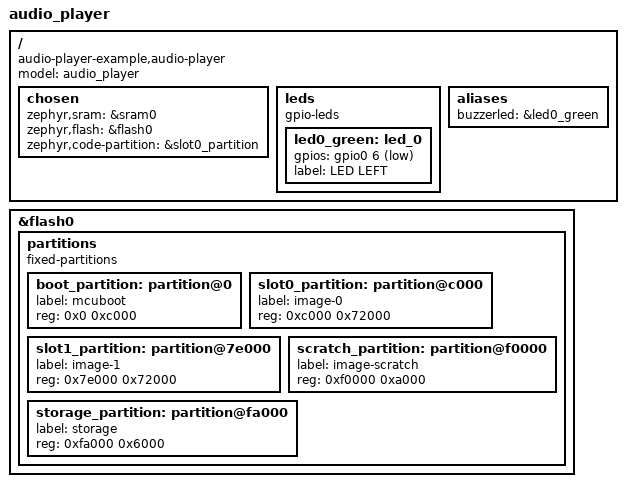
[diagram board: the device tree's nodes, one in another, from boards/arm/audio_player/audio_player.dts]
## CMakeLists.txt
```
# SPDX-License-Identifier: Apache-2.0

cmake_minimum_required(VERSION 3.20.0)

find_package(Zephyr REQUIRED HINTS $ENV{ZEPHYR_BASE})
project(nrf52-pwm-wav-sbc-decoder-player)

target_sources(app PRIVATE
  lib/sbc-1.5/sbc/sbc_primitives.c
  lib/sbc-1.5/sbc/sbc.c

  src/audio/PWMPlayer.cpp
  src/main.cpp
)

zephyr_include_directories(
  lib/sbc-1.5/sbc
  src/audio
  src
)
```

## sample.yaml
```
sample:
  description: NRF52 audio player with PWM output and sbc decoding
    application
  name: nrf52-pwm-with-opus-player
common:
    tags: introduction
    integration_platforms:
      - native_posix
    harness: console
```

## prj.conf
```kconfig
CONFIG_LOG=y
CONFIG_LOG_BUFFER_SIZE=2048
#CONFIG_BT_DEBUG_LOG=y

# kernel options
CONFIG_INIT_STACKS=y

CONFIG_NRFX_PWM=y
CONFIG_NRFX_PWM0=y

CONFIG_CONSOLE=y
CONFIG_USE_SEGGER_RTT=y
CONFIG_RTT_CONSOLE=y

CONFIG_NEWLIB_LIBC=y
CONFIG_MAIN_STACK_SIZE=4096
CONFIG_HEAP_MEM_POOL_SIZE=2048

# required for flashing with west and an external probe
# see https://developer.nordicsemi.com/nRF_Connect_SDK/doc/latest/zephyr/boards/arm/nrf52840dongle_nrf52840/doc/index.html#option-3-using-an-external-debug-probe
CONFIG_BOARD_HAS_NRF5_BOOTLOADER=n
```

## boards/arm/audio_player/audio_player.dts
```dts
// Copyright (c) 2021 Nordic Semiconductor ASA
// SPDX-License-Identifier: Apache-2.0

/dts-v1/;
#include <nordic/nrf52840_qiaa.dtsi>

/ {
	model = "audio_player";
	compatible = "audio-player-example,audio-player";

	chosen {
		zephyr,sram = &sram0;
		zephyr,flash = &flash0;
		zephyr,code-partition = &slot0_partition;
	};

	leds {
		compatible = "gpio-leds";
		led0_green: led_0 {
			gpios = <&gpio0 6 GPIO_ACTIVE_LOW>;
			label = "LED LEFT";
		};
	};

	aliases {
		buzzerled = &led0_green;
	};
};

&flash0 {
	partitions {
		compatible = "fixed-partitions";
		#address-cells = <1>;
		#size-cells = <1>;

		boot_partition: partition@0 {
			label = "mcuboot";
			reg = <0x0 0xc000>;
		};
		slot0_partition: partition@c000 {
			label = "image-0";
			reg = <0xc000 0x72000>;
		};
		slot1_partition: partition@7e000 {
			label = "image-1";
			reg = <0x7e000 0x72000>;
		};
		scratch_partition: partition@f0000 {
			label = "image-scratch";
			reg = <0xf0000 0xa000>;
		};
		storage_partition: partition@fa000 {
			label = "storage";
			reg = <0xfa000 0x6000>;
		};
	};
};
```

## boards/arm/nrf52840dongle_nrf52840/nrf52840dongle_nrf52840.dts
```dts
/dts-v1/;
#include <nordic/nrf52840_qiaa.dtsi>
```

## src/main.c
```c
#include <zephyr.h>
#include <device.h>
#include <devicetree.h>

#include <drivers/gpio.h>

#include <nrfx_pwm.h>
#include <hal/nrf_gpio.h>

#include "audio/buzzer02_16kHz.h"
#include "audio/buzzer01_16kHz.h"
#include "audio/decoder.h"

#include "nrf_pwm_audio.h"

#include <logging/log.h>
LOG_MODULE_REGISTER(main, CONFIG_LOG_DEFAULT_LEVEL);

#define LED0        DT_GPIO_LABEL(LED0_NODE, gpios)
#define LED0_NODE   DT_ALIAS(led0)
#define LED_PIN     DT_GPIO_PIN(LED0_NODE, gpios)
#define LED_FLAGS   DT_GPIO_FLAGS(LED0_NODE, gpios)

#define AUDIO_PIN NRF_GPIO_PIN_MAP(0,15)

void ledInit() {
	const struct device *dev = device_get_binding(LED0);	
	gpio_pin_configure(dev, LED_PIN, GPIO_OUTPUT_ACTIVE | LED_FLAGS);
}

void ledOn(bool on) {
	const struct device *dev = device_get_binding(LED0);
	gpio_pin_set(dev, LED_PIN, on);
}

void main(void) {

	LOG_INF("Playback time!");
	ledInit();
	
	IRQ_DIRECT_CONNECT(PWM0_IRQn, 0, nrfx_pwm_0_irq_handler, 0);
	nrf_pwm_audio_init(AUDIO_PIN, false);

	const size_t PCM_SIZE = 34688;
	unsigned char * pcmResult = (unsigned char *)k_malloc(PCM_SIZE);
    decodeSbcFile(&buzzer01_16kHz, buzzer01_16kHz_size, pcmResult);
	nrf_pwm_audio_playback(pcmResult, PCM_SIZE, NRF_PWM_AUDIO_SAMPLERATE_16K, 3.0, 0);

	ledOn(true);
	while (nrf_pwm_audio_is_playing()) { __WFE(); }
	ledOn(false);

	nrf_pwm_audio_stop();
	k_free(pcmResult);

  	while (1) {
		  k_msleep(2000);
	}
}
```

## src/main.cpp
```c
#include <zephyr.h>

#include <hal/nrf_gpio.h>

#include "audio/PWMPlayer.h"
#include "audio/AudioDecoderSbc.h"
#include "audio/AudioDecoderRaw.h"

#include "samples/sample_hit_raw.h"
#include "samples/sample_itsworking_sbc.h"

#include <logging/log.h>
LOG_MODULE_REGISTER(main, CONFIG_LOG_DEFAULT_LEVEL);

#define AUDIO_PIN NRF_GPIO_PIN_MAP(0,13)

void playRaw(PWMPlayer * player, const unsigned char * data, size_t size) {
	AudioDecoderRaw decoder(data, size, SAMPLERATE_16K);
	player->play(&decoder, 2.0);
	while(player->isPlaying()) { __WFE(); }
}

void playSbc(PWMPlayer * player, const unsigned char * data, size_t size) {
	AudioDecoderSbc decoder(data, size);
	player->play(&decoder, 2.0);
	while(player->isPlaying()) { __WFE(); }
}


extern "C" void main(void) {
	LOG_INF("Playback time!!");
	IRQ_DIRECT_CONNECT(PWM0_IRQn, 0, nrfx_pwm_0_irq_handler, 0);

	PWMPlayer player;
	player.init(AUDIO_PIN);

	playRaw(&player, sample_hit_raw, sample_hit_raw_size);
	playSbc(&player, sample_itsworking_sbc, sample_itsworking_sbc_size);
	player.destory();
	
  	while (1) {
		  k_msleep(10000);
	}
}
```

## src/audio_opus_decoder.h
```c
#pragma once

#include <zephyr.h>
#include <stdint.h>
#include "opus.h"
#include "nrftalk_opus.h"
#include "nrf.h"
#include "app_error.h"

#define OPUS_DECODER_SIZE 9224
#define AUDIO_SAMPLING_FREQUENCY 8000
#define AUDIO_CHANNEL 1

#define AUDIO_FRAME_SIZE_MS 5 // ms of each frame
#define AUDIO_BITRATE_LIMIT 11000 // bits per second
#define AUDIO_FRAME_SIZE_SAMPLES (AUDIO_FRAME_SIZE_MS * AUDIO_SAMPLING_FREQUENCY / 1000)

#define OPUS_AUDIO_FRAME_SIZE_BYTES ((AUDIO_BITRATE_LIMIT * AUDIO_FRAME_SIZE_SAMPLES / (8 * AUDIO_SAMPLING_FREQUENCY)))

#include <logging/log.h>

__ALIGN(4) static uint8_t           m_opus_decoder[OPUS_DECODER_SIZE];
static OpusDecoder * const          m_opus_state_decoder = (OpusDecoder *) m_opus_decoder;

typedef struct {
    uint16_t    data_size;
	uint8_t     data[OPUS_AUDIO_FRAME_SIZE_BYTES];
} opus_frame_t;

void opus_init() {
    size_t decoder_size = opus_decoder_get_size(AUDIO_CHANNEL);
    if (decoder_size != OPUS_DECODER_SIZE) {
        printk("error while checking decoder size. Please adjust to: %d\n", decoder_size);
    }
    int res = opus_decoder_init(m_opus_state_decoder, AUDIO_SAMPLING_FREQUENCY, AUDIO_CHANNEL);
    if (res != OPUS_OK) {
        printk("error while initializing opus decoder\n");
    } else {
        printk("opus decoder initialized\n");
    }
}

void play() {
    int16_t out[AUDIO_FRAME_SIZE_SAMPLES * AUDIO_CHANNEL * sizeof(uint16_t)];

    opus_frame_t frame;
    memcpy(frame.data, nrfistalking_opus_8kHz_32k, OPUS_AUDIO_FRAME_SIZE_BYTES);
    frame.data_size = OPUS_AUDIO_FRAME_SIZE_BYTES;

    drv_audio_codec_decode(&frame, out);

    int spf = opus_packet_get_samples_per_frame(nrfistalking_opus_8kHz_32k, AUDIO_SAMPLING_FREQUENCY);
    int bandwidth = opus_packet_get_bandwidth(nrfistalking_opus_8kHz_32k);
    int channels = opus_packet_get_nb_channels(nrfistalking_opus_8kHz_32k);
    printk("samples per frame: %d, bandwith: %d, channels: %d\n", spf, bandwidth, channels); // 160
}

void drv_audio_codec_decode(opus_frame_t *p_frame, int16_t *output_samples) {
    int ret;
    
    ret = opus_decode(
            m_opus_state_decoder,
            (p_frame->data_size == 0)? NULL :p_frame->data,
			p_frame->data_size,
			output_samples,
			AUDIO_FRAME_SIZE_SAMPLES,
			0);
   if(ret != AUDIO_FRAME_SIZE_SAMPLES){
	   printk("decode fail with error: %d!\n",ret);
   }

}
```

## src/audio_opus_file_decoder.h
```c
#pragma once

#include <zephyr.h>
#include <stdint.h>
#include "opusfile.h"
#include "nrftalk_opus.h"
#include "nrf.h"
#include "app_error.h"

int opus_mem_pos = 0;

void play() {
    int err = 0;
    OggOpusFile * oggFile = op_open_memory(nrfistalking_opus_8kHz_32k, nrfistalking_opus_8kHz_32k_size, &err);
    if (err == 0) {
        printk("open opus file worked!\n");
    } else {
        printk("error during opus file opening: %d\n", err);
    }
    opus_int16 data[1000] = {0};
    int sampleCount = op_read(oggFile, (opus_int16 *)&data, 1000, NULL);
    if (sampleCount < 0) {
        printk("error during reading ogg file: %d\n", sampleCount);
    } else {
        printk("%d samples read\n", sampleCount);
    }
}
```

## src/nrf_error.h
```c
/*
 * Copyright (c) Nordic Semiconductor ASA
 * All rights reserved.
 *
 * Redistribution and use in source and binary forms, with or without modification,
 * are permitted provided that the following conditions are met:
 *
 *   1. Redistributions of source code must retain the above copyright notice, this
 *   list of conditions and the following disclaimer.
 *
 *   2. Redistributions in binary form must reproduce the above copyright notice, this
 *   list of conditions and the following disclaimer in the documentation and/or
 *   other materials provided with the distribution.
 *
 *   3. Neither the name of Nordic Semiconductor ASA nor the names of other
 *   contributors to this software may be used to endorse or promote products
 *   derived from this software without specific prior written permission.
 *
 *   4. This software must only be used in a processor manufactured by Nordic
 *   Semiconductor ASA, or in a processor manufactured by a third party that
 *   is used in combination with a processor manufactured by Nordic Semiconductor.
 *
 *
 * THIS SOFTWARE IS PROVIDED BY THE COPYRIGHT HOLDERS AND CONTRIBUTORS "AS IS" AND
 * ANY EXPRESS OR IMPLIED WARRANTIES, INCLUDING, BUT NOT LIMITED TO, THE IMPLIED
 * WARRANTIES OF MERCHANTABILITY AND FITNESS FOR A PARTICULAR PURPOSE ARE
 * DISCLAIMED. IN NO EVENT SHALL THE COPYRIGHT HOLDER OR CONTRIBUTORS BE LIABLE FOR
 * ANY DIRECT, INDIRECT, INCIDENTAL, SPECIAL, EXEMPLARY, OR CONSEQUENTIAL DAMAGES
 * (INCLUDING, BUT NOT LIMITED TO, PROCUREMENT OF SUBSTITUTE GOODS OR SERVICES;
 * LOSS OF USE, DATA, OR PROFITS; OR BUSINESS INTERRUPTION) HOWEVER CAUSED AND ON
 * ANY THEORY OF LIABILITY, WHETHER IN CONTRACT, STRICT LIABILITY, OR TORT
 * (INCLUDING NEGLIGENCE OR OTHERWISE) ARISING IN ANY WAY OUT OF THE USE OF THIS
 * SOFTWARE, EVEN IF ADVISED OF THE POSSIBILITY OF SUCH DAMAGE.
 *
 */
 /**
  @defgroup nrf_error SoftDevice Global Error Codes
  @{

  @brief Global Error definitions
*/

/* Header guard */
#ifndef NRF_ERROR_H__
#define NRF_ERROR_H__

#ifdef __cplusplus
extern "C" {
#endif

/** @defgroup NRF_ERRORS_BASE Error Codes Base number definitions
 * @{ */
#define NRF_ERROR_BASE_NUM      (0x0)       ///< Global error base
#define NRF_ERROR_SDM_BASE_NUM  (0x1000)    ///< SDM error base
#define NRF_ERROR_SOC_BASE_NUM  (0x2000)    ///< SoC error base
#define NRF_ERROR_STK_BASE_NUM  (0x3000)    ///< STK error base
/** @} */

#define NRF_SUCCESS                           (NRF_ERROR_BASE_NUM + 0)  ///< Successful command
#define NRF_ERROR_SVC_HANDLER_MISSING         (NRF_ERROR_BASE_NUM + 1)  ///< SVC handler is missing
#define NRF_ERROR_SOFTDEVICE_NOT_ENABLED      (NRF_ERROR_BASE_NUM + 2)  ///< SoftDevice has not been enabled
#define NRF_ERROR_INTERNAL                    (NRF_ERROR_BASE_NUM + 3)  ///< Internal Error
#define NRF_ERROR_NO_MEM                      (NRF_ERROR_BASE_NUM + 4)  ///< No Memory for operation
#define NRF_ERROR_NOT_FOUND                   (NRF_ERROR_BASE_NUM + 5)  ///< Not found
#define NRF_ERROR_NOT_SUPPORTED               (NRF_ERROR_BASE_NUM + 6)  ///< Not supported
#define NRF_ERROR_INVALID_PARAM               (NRF_ERROR_BASE_NUM + 7)  ///< Invalid Parameter
#define NRF_ERROR_INVALID_STATE               (NRF_ERROR_BASE_NUM + 8)  ///< Invalid state, operation disallowed in this state
#define NRF_ERROR_INVALID_LENGTH              (NRF_ERROR_BASE_NUM + 9)  ///< Invalid Length
#define NRF_ERROR_INVALID_FLAGS               (NRF_ERROR_BASE_NUM + 10) ///< Invalid Flags
#define NRF_ERROR_INVALID_DATA                (NRF_ERROR_BASE_NUM + 11) ///< Invalid Data
#define NRF_ERROR_DATA_SIZE                   (NRF_ERROR_BASE_NUM + 12) ///< Invalid Data size
#define NRF_ERROR_TIMEOUT                     (NRF_ERROR_BASE_NUM + 13) ///< Operation timed out
#define NRF_ERROR_NULL                        (NRF_ERROR_BASE_NUM + 14) ///< Null Pointer
#define NRF_ERROR_FORBIDDEN                   (NRF_ERROR_BASE_NUM + 15) ///< Forbidden Operation
#define NRF_ERROR_INVALID_ADDR                (NRF_ERROR_BASE_NUM + 16) ///< Bad Memory Address
#define NRF_ERROR_BUSY                        (NRF_ERROR_BASE_NUM + 17) ///< Busy
#define NRF_ERROR_CONN_COUNT                  (NRF_ERROR_BASE_NUM + 18) ///< Maximum connection count exceeded.
#define NRF_ERROR_RESOURCES                   (NRF_ERROR_BASE_NUM + 19) ///< Not enough resources for operation

#ifdef __cplusplus
}
#endif
#endif // NRF_ERROR_H__

/**
  @}
*/
```

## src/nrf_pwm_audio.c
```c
/**
 *  - - - - - - - - - - - - - - - - - - - - - - - - - - - - - - - - - - - - -
 *
 *  @file     nrf_pwm_audio.c
 *  @author   Tamas Harczos
 *  @since    2019-10-01
 *  @version  0.1.0
 *  @licence  GNU LGPL v3 (https://www.gnu.org/licenses/lgpl-3.0.txt)
 * 
 *  @brief    PWM audio functionality on nRF52.
 *  
 *  Project homepage:  https://nrf52-pwm-audio.sourceforge.io/
 *  Youtube video:     https://youtu.be/_m4-pH_Yw3M
 *
 *  - - - - - - - - - - - - - - - - - - - - - - - - - - - - - - - - - - - - -
 *
 *  This program is free software: you can redistribute it and/or modify
 *  it under the terms of the GNU Lesser General Public License as published
 *  by the Free Software Foundation, either version 3 of the License, or
 *  (at your option) any later version.
 *
 *  This program is distributed in the hope that it will be useful,
 *  but WITHOUT ANY WARRANTY; without even the implied warranty of
 *  MERCHANTABILITY or FITNESS FOR A PARTICULAR PURPOSE.  See the
 *  GNU Lesser General Public License for more details.
 *
 *  You should have received a copy of the GNU Lesser General Public License
 *  along with this program.  If not, see <http://www.gnu.org/licenses/>.
 *
 *  - - - - - - - - - - - - - - - - - - - - - - - - - - - - - - - - - - - - -
 *
**/


// *******************************************************************************************************************
// Included Files (from specific to general)
// *******************************************************************************************************************

#include "nrf_pwm_audio.h"
#include <hal/nrf_gpio.h>


// *******************************************************************************************************************
// Definitions
// *******************************************************************************************************************

bool static m_pwm_initialized= false;                                       ///< gets true during successful init(), becomes false during destroy()
bool static m_pwm_playback_in_progress= false;                              ///< every SPI transfers sets this flag and the 'SPI finished' callback clears it

nrf_pwm_sequence_t static m_pwm_seqs[2]= {0};                               ///< allocate memory for two PWM sequence structures
uint16_t static m_seq_buf[2][NRF_PWM_AUDIO_BUFFER_LENGTH]= {0};             ///< allocate memory for two sequence buffers

nrfx_pwm_t static m_pwm= NRFX_PWM_INSTANCE(NRF_PWM_AUDIO_PWM_INSTANCE);     ///< instantiate one PWM peripheral

#define NRF_PWM_AUDIO_COUNTERTOP 512                                        ///< this implies the supported sampling rates and gains; I suggest not to change it unless you know exactly what you are doing :)

nrf_pwm_audio_samplerate_t static m_upsample= NRF_PWM_AUDIO_SAMPLERATE_31K; ///< sampling rate
float static m_gain= 1.0f;                                                  ///< gain to be applied at playback

size_t static m_num_repeat= 0;                                              ///< number of repeats (after the first playback) requested
size_t static m_num_repeat_left= 0;                                         ///< number of repeats left

int8_t static const *m_pcm_data= NULL;                                      ///< pointer to the PCM values
size_t static m_pcm_data_length= 0;                                         ///< number of elements at the PCM data pointer
size_t static m_pcm_data_read_idx= 0;                                       ///< current PCM buffer read index 
size_t static m_num_sample_left= 0;                                         ///< PCM values left to be processed


// *******************************************************************************************************************
// Module internal functions
// *******************************************************************************************************************

//////////////////////////////////////////////////////////////////////////////////////////////////////////////////////
///
/// @brief Convert a buffer of PCM values into a PWM sequence.
///
/// @param[out]  pwm_seq_buffer  Pointer to the 16-bit unsigned buffer of the PWM sequence items.
/// @param[in]   pcm_buffer      Pointer to the 8-bit signed integer PCM values to be converted.
/// @param[in]   pcm_buf_length  Length of pcm_buffer.
/// @param[in    samplerate      Sample rate of the PCM data (8 kHz, 16 kHz, or 31 kHz).
/// @param[in]   scaler          Gain to be applied (2.0 ~= +6 dB).
///
/// @return  Number of bytes consumed from the pcm_buffer.
///
/// @note  pwm_seq_buffer must be able to hold enough data (in worst case pcm_buf_length*2 bytes).
///
//////////////////////////////////////////////////////////////////////////////////////////////////////////////////////
size_t static pcm_to_pwm(uint16_t *pwm_seq_buffer, int8_t const *pcm_buffer, size_t pcm_buf_length, nrf_pwm_audio_samplerate_t samplerate, float scaler)
{
  size_t srf= (size_t) samplerate;
  float sample;

  for (size_t i=0; i<NRF_PWM_AUDIO_BUFFER_LENGTH; ++i)
  {
    if (i/srf < pcm_buf_length)
    {
      sample= ((float) pcm_buffer[i/srf]) * (scaler / 128.0f);
    }
    else
    {
      sample= 1.0f;
    }

    if ((sample > -1.0f) && (sample < 1.0f))
    {
      pwm_seq_buffer[i]= (uint16_t) ((sample+1.0f) * ((float) NRF_PWM_AUDIO_COUNTERTOP) / 2.0f);
    }
    else if (sample == 0)
    {
      pwm_seq_buffer[i]= NRF_PWM_AUDIO_COUNTERTOP / 2;
    }
    else if (sample <= -1.0f)
    {
      pwm_seq_buffer[i]= 0;
    }
    else if (sample >= 1.0f)
    {
      pwm_seq_buffer[i]= NRF_PWM_AUDIO_COUNTERTOP;
    }
  }

  return (NRF_PWM_AUDIO_BUFFER_LENGTH/srf);
}


//////////////////////////////////////////////////////////////////////////////////////////////////////////////////////
///
/// @brief  Event handler of the PWM periphery. Handles filling of the PWM buffers.
///
//////////////////////////////////////////////////////////////////////////////////////////////////////////////////////
static void pwm_handler(nrfx_pwm_evt_type_t event_type, void * p_context)
{
  size_t i, consumed_pcm_samples= 0;

  switch (event_type)
  {
    case NRFX_PWM_EVT_END_SEQ0:

      if (m_pwm_playback_in_progress)
      {
        consumed_pcm_samples= pcm_to_pwm(m_seq_buf[0], &m_pcm_data[m_pcm_data_read_idx], m_num_sample_left, m_upsample, m_gain);
      }
      else
      {
        for (i=0; i<NRF_PWM_AUDIO_BUFFER_LENGTH; ++i) { m_seq_buf[0][i]= NRF_PWM_AUDIO_COUNTERTOP / 2; }
      }

    break;

    case NRFX_PWM_EVT_END_SEQ1:

      if (m_pwm_playback_in_progress)
      {
        consumed_pcm_samples= pcm_to_pwm(m_seq_buf[1], &m_pcm_data[m_pcm_data_read_idx], m_num_sample_left, m_upsample, m_gain);
      }
      else
      {
        for (i=0; i<NRF_PWM_AUDIO_BUFFER_LENGTH; ++i) { m_seq_buf[1][i]= NRF_PWM_AUDIO_COUNTERTOP / 2; }
      }

    break;

    default:
    return;
  }

  m_pcm_data_read_idx += consumed_pcm_samples;
  m_num_sample_left -= consumed_pcm_samples;

  if (m_pcm_data_read_idx >= m_pcm_data_length)
  {
    if (m_num_repeat_left > 0)
    {
      m_num_repeat_left--;
      m_num_sample_left = m_pcm_data_length;
      m_pcm_data_read_idx= 0;
    }
    else
    {
      m_num_sample_left= 0;
      m_pwm_playback_in_progress= false;
    }
  }
}


//////////////////////////////////////////////////////////////////////////////////////////////////////////////////////
///
/// @brief Fills both PWM sequence buffers with neutral values.
///
//////////////////////////////////////////////////////////////////////////////////////////////////////////////////////
static void clear_buffers(void)
{
  for (size_t i=0; i<NRF_PWM_AUDIO_BUFFER_LENGTH; ++i)
  {
    m_seq_buf[0][i]= m_seq_buf[1][i]= NRF_PWM_AUDIO_COUNTERTOP / 2;
  }
}


// *******************************************************************************************************************
// Public functions
// *******************************************************************************************************************

//////////////////////////////////////////////////////////////////////////////////////////////////////////////////////
nrfx_err_t nrf_pwm_audio_init(uint8_t gpio_pin, bool high_drive)
{
  nrfx_err_t retCode;

  // - - - - - - - - - - - - - - - - - - - - - - - - - - - - - - - - - - - - - - - - - - - - - - -
  // check if PWM was already initialized (yes -> this function was not called for the first time)
  if (m_pwm_initialized)
  {
    nrf_pwm_audio_destroy();
  }

  // - - - - - - - - - - - - - - - - - - - - - - - - - - - - - - - - - - - - - - - - - - - - - - -
  nrfx_pwm_config_t const pwm_config= 
  {
    .output_pins  = { gpio_pin | NRFX_PWM_PIN_INVERTED,
                      NRFX_PWM_PIN_NOT_USED,
                      NRFX_PWM_PIN_NOT_USED,
                      NRFX_PWM_PIN_NOT_USED },
    .irq_priority = NRF_PWM_AUDIO_PRIORITY,
    .base_clock   = NRF_PWM_CLK_16MHz,
    .count_mode   = NRF_PWM_MODE_UP,
    .top_value    = NRF_PWM_AUDIO_COUNTERTOP,
    .load_mode    = PWM_DECODER_LOAD_Common,
    .step_mode    = PWM_DECODER_MODE_RefreshCount      
  };

  retCode= nrfx_pwm_init(&m_pwm, &pwm_config, pwm_handler, NULL);
  if (NRFX_SUCCESS != retCode) { return retCode; }

  // - - - - - - - - - - - - - - - - - - - - - - - - - - - - - - - - - - - - - - - - - - - - - - -
  clear_buffers();

  // - - - - - - - - - - - - - - - - - - - - - - - - - - - - - - - - - - - - - - - - - - - - - - -
  if (high_drive)
  {
    nrf_gpio_cfg(gpio_pin, NRF_GPIO_PIN_DIR_OUTPUT, NRF_GPIO_PIN_INPUT_DISCONNECT, NRF_GPIO_PIN_NOPULL, NRF_GPIO_PIN_H0S1, NRF_GPIO_PIN_NOSENSE);
  }

  // - - - - - - - - - - - - - - - - - - - - - - - - - - - - - - - - - - - - - - - - - - - - - - -
  m_pwm_seqs[0].values= ((nrf_pwm_values_t) ((uint16_t const*) m_seq_buf[0]));
  m_pwm_seqs[0].length= NRF_PWM_AUDIO_BUFFER_LENGTH;
  m_pwm_seqs[0].repeats= 0;
  m_pwm_seqs[0].end_delay= 0;

  m_pwm_seqs[1].values= ((nrf_pwm_values_t) ((uint16_t const*) m_seq_buf[1]));
  m_pwm_seqs[1].length= NRF_PWM_AUDIO_BUFFER_LENGTH;
  m_pwm_seqs[1].repeats= 0;
  m_pwm_seqs[1].end_delay= 0;

  m_pwm_initialized= true;

  // - - - - - - - - - - - - - - - - - - - - - - - - - - - - - - - - - - - - - - - - - - - - - - - - - - - - - - - - - - - - - - - - - - - - - - - - - - - - -
  return NRFX_SUCCESS;
}


//////////////////////////////////////////////////////////////////////////////////////////////////////////////////////
void nrf_pwm_audio_destroy(void)
{
  if (m_pwm_initialized)
  {
    nrf_pwm_audio_stop();
    nrfx_pwm_uninit(&m_pwm);
  }

  m_pwm_playback_in_progress= false;
  m_pwm_initialized= false;
}


//////////////////////////////////////////////////////////////////////////////////////////////////////////////////////
nrfx_err_t nrf_pwm_audio_playback(uint8_t const *pcm_data, size_t pcm_data_length, nrf_pwm_audio_samplerate_t samplerate, float gain, size_t num_repeat)
{
  if (!m_pwm_initialized) { return NRFX_ERROR_INTERNAL; }

  m_pcm_data= pcm_data;
  m_pcm_data_length= pcm_data_length;
  m_upsample= samplerate;
  m_gain= gain;
  m_num_repeat= num_repeat;

  m_pcm_data_read_idx= 0;
  m_num_repeat_left= num_repeat;
  m_num_sample_left= pcm_data_length;

  m_pwm_playback_in_progress= true;

  nrfx_pwm_complex_playback(&m_pwm, &m_pwm_seqs[0], &m_pwm_seqs[1], 1, NRFX_PWM_FLAG_SIGNAL_END_SEQ0 | NRFX_PWM_FLAG_SIGNAL_END_SEQ1 | NRFX_PWM_FLAG_LOOP);

  return NRFX_SUCCESS;
}


//////////////////////////////////////////////////////////////////////////////////////////////////////////////////////
nrfx_err_t nrf_pwm_audio_stop(void)
{
  if (!m_pwm_initialized) { return NRFX_ERROR_INTERNAL; }

  nrfx_pwm_stop(&m_pwm, false);

  clear_buffers();

  return NRFX_SUCCESS;
}


//////////////////////////////////////////////////////////////////////////////////////////////////////////////////////
size_t nrf_pwm_audio_repeats_left(void)
{
  return (m_pwm_initialized)?(m_num_repeat_left):(0);
}


//////////////////////////////////////////////////////////////////////////////////////////////////////////////////////
size_t nrf_pwm_audio_samples_left(void)
{
  return (m_pwm_initialized)?(m_num_sample_left):(0);
}


//////////////////////////////////////////////////////////////////////////////////////////////////////////////////////
bool nrf_pwm_audio_is_playing(void)
{
  return (m_pwm_initialized)?(m_pwm_playback_in_progress):(false);
}



// *******************************************************************************************************************
// End of File
// *******************************************************************************************************************
```

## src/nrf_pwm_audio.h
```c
/**
 *  - - - - - - - - - - - - - - - - - - - - - - - - - - - - - - - - - - - - -
 *
 *  @file     nrf_pwm_audio.h
 *  @author   Tamas Harczos
 *  @since    2019-10-01
 *  @version  0.1.0
 *  @licence  GNU LGPL v3 (https://www.gnu.org/licenses/lgpl-3.0.txt)
 * 
 *  @brief    PWM audio functionality on nRF52.
 *  
 *  Project homepage:  https://nrf52-pwm-audio.sourceforge.io/
 *  Youtube video:     https://youtu.be/_m4-pH_Yw3M
 *
 *  - - - - - - - - - - - - - - - - - - - - - - - - - - - - - - - - - - - - -
 *
 *  This program is free software: you can redistribute it and/or modify
 *  it under the terms of the GNU Lesser General Public License as published
 *  by the Free Software Foundation, either version 3 of the License, or
 *  (at your option) any later version.
 *
 *  This program is distributed in the hope that it will be useful,
 *  but WITHOUT ANY WARRANTY; without even the implied warranty of
 *  MERCHANTABILITY or FITNESS FOR A PARTICULAR PURPOSE.  See the
 *  GNU Lesser General Public License for more details.
 *
 *  You should have received a copy of the GNU Lesser General Public License
 *  along with this program.  If not, see <http://www.gnu.org/licenses/>.
 *
 *  - - - - - - - - - - - - - - - - - - - - - - - - - - - - - - - - - - - - -
 *
**/


#ifndef _NRF_PWM_AUDIO_H
#define _NRF_PWM_AUDIO_H



// *******************************************************************************************************************
// Included Files (from specific to general)
// *******************************************************************************************************************

#include "nrfx_pwm.h"

#include <stdbool.h>
#include <stdint.h>



// *******************************************************************************************************************
// Provide C++ Compatibility
// *******************************************************************************************************************

#ifdef __cplusplus
extern "C"
{
#endif

               
               
// *******************************************************************************************************************
// Global declarations
// *******************************************************************************************************************

#define NRF_PWM_AUDIO_PWM_INSTANCE  0         ///< the number of PWM instance to use
#define NRF_PWM_AUDIO_BUFFER_LENGTH 512       ///< length of each of the two PWM sequence buffers
#define NRF_PWM_AUDIO_PRIORITY      6         ///< requested priority of the PWM peripheral


typedef enum
{
  NRF_PWM_AUDIO_SAMPLERATE_31K = 1,           ///< use 31250 Hz sampling rate
  NRF_PWM_AUDIO_SAMPLERATE_16K = 2,           ///< use 15625 Hz sampling rate
  NRF_PWM_AUDIO_SAMPLERATE_8K  = 4            ///< use 7812.5 Hz sampling rate
} nrf_pwm_audio_samplerate_t;


// *******************************************************************************************************************
// Public functions
// *******************************************************************************************************************

//////////////////////////////////////////////////////////////////////////////////////////////////////////////////////
///
/// @brief  Initialize the PWM periphery and clear buffers.
///
/// @param[in]  gpio_pin    Number of the GPIO pin to be used as output.
/// @param[in]  high_drive  Whether to enable higher output drive strength for more loudness.
///
/// @return  NRFX_SUCCESS on success or an NRFX_ERROR_* code (as listed in nrfx_glue.h) upon failure.
///
/// @note  This function should be called before calling any other function from this module.
///
//////////////////////////////////////////////////////////////////////////////////////////////////////////////////////
nrfx_err_t nrf_pwm_audio_init(uint8_t gpio_pin, bool high_drive);


//////////////////////////////////////////////////////////////////////////////////////////////////////////////////////
///
/// @brief  Stops any running PWM playback and uninitializes the PWM periphery.
///
//////////////////////////////////////////////////////////////////////////////////////////////////////////////////////
void nrf_pwm_audio_destroy(void);


//////////////////////////////////////////////////////////////////////////////////////////////////////////////////////
///
/// @brief  Initiates a playback of the given audio clip.
///
/// @param[in]  pcm_data         Pointer to the 8-bit signed integer PCM audio data.
/// @param[in]  pcm_data_length  Number of samples to be played back.
/// @param[in]  samplerate       Desired sample rate for the playback (8 kHz, 16 kHz, or 31 kHz).
/// @param[in]  gain             Gain to be applied before playback (2.0 ~= +6 dB).
/// @param[in]  num_repeat       Number of repeats after the first playback.
///
/// @return  NRFX_SUCCESS on success or NRFX_ERROR_INTERNAL if the module has not been initialized previously.
///
/// @note  With the default PWM clock (16 MHz) and COUNTERTOP setting (512) it is safe to apply a gain <= 2.0 without
///        the risk of distortion.
///
//////////////////////////////////////////////////////////////////////////////////////////////////////////////////////
nrfx_err_t nrf_pwm_audio_playback(uint8_t const *pcm_data, size_t pcm_data_length, nrf_pwm_audio_samplerate_t samplerate, float gain, size_t num_repeat);


//////////////////////////////////////////////////////////////////////////////////////////////////////////////////////
///
/// @brief  Stops any running playback, clears the buffers, and stops the PWM periphery (but leaves it initialized).
///
/// @return  NRFX_SUCCESS on success or NRFX_ERROR_INTERNAL if the module has not been initialized previously.
///
//////////////////////////////////////////////////////////////////////////////////////////////////////////////////////
nrfx_err_t nrf_pwm_audio_stop(void);


//////////////////////////////////////////////////////////////////////////////////////////////////////////////////////
///
/// @brief  Returns the number of repeats left. If the module has not yet been initialized, the function returns 0.
///
//////////////////////////////////////////////////////////////////////////////////////////////////////////////////////
size_t nrf_pwm_audio_repeats_left(void);


//////////////////////////////////////////////////////////////////////////////////////////////////////////////////////
///
/// @brief  Returns the number of samples still to be played back in the current loop. To calculate the total number
///         of samples still to be played back, use the following formula: 
///         pcm_data_length * nrf_pwm_audio_repeats_left() + nrf_pwm_audio_samples_left().
///         If the module has not yet been initialized, the function returns 0.
///
//////////////////////////////////////////////////////////////////////////////////////////////////////////////////////
size_t nrf_pwm_audio_samples_left(void);


//////////////////////////////////////////////////////////////////////////////////////////////////////////////////////
///
/// @brief  Return true if audio playback is currently active. If the module has not yet been initialized, the
///         function returns false.
///
//////////////////////////////////////////////////////////////////////////////////////////////////////////////////////
bool nrf_pwm_audio_is_playing(void);



  
// *******************************************************************************************************************
// Provide C++ Compatibility
// *******************************************************************************************************************
#ifdef __cplusplus
}
#endif


#endif // _NRF_PWM_AUDIO_H



// *******************************************************************************************************************
// End of File
// *******************************************************************************************************************
```

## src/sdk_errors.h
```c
/**
 * Copyright (c) 2013 - 2018, Nordic Semiconductor ASA
 * 
 * All rights reserved.
 * 
 * Redistribution and use in source and binary forms, with or without modification,
 * are permitted provided that the following conditions are met:
 * 
 * 1. Redistributions of source code must retain the above copyright notice, this
 *    list of conditions and the following disclaimer.
 * 
 * 2. Redistributions in binary form, except as embedded into a Nordic
 *    Semiconductor ASA integrated circuit in a product or a software update for
 *    such product, must reproduce the above copyright notice, this list of
 *    conditions and the following disclaimer in the documentation and/or other
 *    materials provided with the distribution.
 * 
 * 3. Neither the name of Nordic Semiconductor ASA nor the names of its
 *    contributors may be used to endorse or promote products derived from this
 *    software without specific prior written permission.
 * 
 * 4. This software, with or without modification, must only be used with a
 *    Nordic Semiconductor ASA integrated circuit.
 * 
 * 5. Any software provided in binary form under this license must not be reverse
 *    engineered, decompiled, modified and/or disassembled.
 * 
 * THIS SOFTWARE IS PROVIDED BY NORDIC SEMICONDUCTOR ASA "AS IS" AND ANY EXPRESS
 * OR IMPLIED WARRANTIES, INCLUDING, BUT NOT LIMITED TO, THE IMPLIED WARRANTIES
 * OF MERCHANTABILITY, NONINFRINGEMENT, AND FITNESS FOR A PARTICULAR PURPOSE ARE
 * DISCLAIMED. IN NO EVENT SHALL NORDIC SEMICONDUCTOR ASA OR CONTRIBUTORS BE
 * LIABLE FOR ANY DIRECT, INDIRECT, INCIDENTAL, SPECIAL, EXEMPLARY, OR
 * CONSEQUENTIAL DAMAGES (INCLUDING, BUT NOT LIMITED TO, PROCUREMENT OF SUBSTITUTE
 * GOODS OR SERVICES; LOSS OF USE, DATA, OR PROFITS; OR BUSINESS INTERRUPTION)
 * HOWEVER CAUSED AND ON ANY THEORY OF LIABILITY, WHETHER IN CONTRACT, STRICT
 * LIABILITY, OR TORT (INCLUDING NEGLIGENCE OR OTHERWISE) ARISING IN ANY WAY OUT
 * OF THE USE OF THIS SOFTWARE, EVEN IF ADVISED OF THE POSSIBILITY OF SUCH DAMAGE.
 * 
 */
/**@file
 *
 * @defgroup sdk_error SDK Error codes
 * @{
 * @ingroup app_common
 * @{
 * @details Error codes are 32-bit unsigned integers with the most significant 16-bit reserved for
 *          identifying the module where the error occurred while the least least significant LSB
 *          are used to provide the cause or nature of error. Each module is assigned a 16-bit
 *          unsigned integer. Which it will use to identify all errors that occurred in it. 16-bit
 *          LSB range is with module id as the MSB in the 32-bit error code is reserved for the
 *          module. As an example, if 0x8800 identifies a certain SDK module, all values from
 *          0x88000000 - 0x8800FFFF are reserved for this module.
 *          It should be noted that common error reasons have been assigned values to make it
 *          possible to decode error reason easily. As an example, lets module uninitialized has
 *          been assigned an error code 0x000A0. Then, if application encounters an error code
 *          0xZZZZ00A0, it knows that it accessing a certain module without initializing it.
 *          Apart from this, each module is allowed to define error codes that are not covered by
 *          the common ones, however, these values are defined in a range that does not conflict
 *          with common error values. For module, specific error however, it is possible that the
 *          same error value is used by two different modules to indicated errors of very different
 *          nature. If error is already defined by the NRF common error codes, these are reused.
 *          A range is reserved for application as well, it can use this range for defining
 *          application specific errors.
 *
 * @note Success code, NRF_SUCCESS, does not include any module identifier.

 */

#ifndef SDK_ERRORS_H__
#define SDK_ERRORS_H__

#include <stdint.h>
#include "nrf_error.h"

#ifdef __cplusplus
extern "C" {
#endif

/**
 * @defgroup sdk_err_base Base defined for SDK Modules
 * @{
 */
#define NRF_ERROR_SDK_ERROR_BASE         (NRF_ERROR_BASE_NUM + 0x8000)   /**< Base value defined for SDK module identifiers. */
#define NRF_ERROR_SDK_COMMON_ERROR_BASE  (NRF_ERROR_BASE_NUM + 0x0080)   /**< Base error value to be used for SDK error values. */
/** @} */

/**
 * @defgroup sdk_module_codes Codes reserved as identification for module where the error occurred.
 * @{
 */
#define NRF_ERROR_MEMORY_MANAGER_ERR_BASE   (0x8100)
#define NRF_ERROR_PERIPH_DRIVERS_ERR_BASE   (0x8200)
#define NRF_ERROR_GAZELLE_ERR_BASE          (0x8300)
#define NRF_ERROR_BLE_IPSP_ERR_BASE         (0x8400)
/** @} */


/**
 * @defgroup sdk_iot_errors Codes reserved as identification for IoT errors.
 * @{
 */
#define NRF_ERROR_IOT_ERR_BASE_START        (0xA000)
#define NRF_ERROR_IOT_ERR_BASE_STOP         (0xAFFF)
/** @} */


/**
 * @defgroup sdk_common_errors Codes reserved as identification for common errors.
 * @{
 */
#define NRF_ERROR_MODULE_NOT_INITIALZED      (NRF_ERROR_SDK_COMMON_ERROR_BASE + 0x0000)
#define NRF_ERROR_MUTEX_INIT_FAILED          (NRF_ERROR_SDK_COMMON_ERROR_BASE + 0x0001)
#define NRF_ERROR_MUTEX_LOCK_FAILED          (NRF_ERROR_SDK_COMMON_ERROR_BASE + 0x0002)
#define NRF_ERROR_MUTEX_UNLOCK_FAILED        (NRF_ERROR_SDK_COMMON_ERROR_BASE + 0x0003)
#define NRF_ERROR_MUTEX_COND_INIT_FAILED     (NRF_ERROR_SDK_COMMON_ERROR_BASE + 0x0004)
#define NRF_ERROR_MODULE_ALREADY_INITIALIZED (NRF_ERROR_SDK_COMMON_ERROR_BASE + 0x0005)
#define NRF_ERROR_STORAGE_FULL               (NRF_ERROR_SDK_COMMON_ERROR_BASE + 0x0006)
#define NRF_ERROR_API_NOT_IMPLEMENTED        (NRF_ERROR_SDK_COMMON_ERROR_BASE + 0x0010)
#define NRF_ERROR_FEATURE_NOT_ENABLED        (NRF_ERROR_SDK_COMMON_ERROR_BASE + 0x0011)
/** @} */


/**
 * @defgroup drv_specific_errors Error / status codes specific to drivers.
 * @{
 */
#define NRF_ERROR_DRV_TWI_ERR_OVERRUN        (NRF_ERROR_PERIPH_DRIVERS_ERR_BASE + 0x0000)
#define NRF_ERROR_DRV_TWI_ERR_ANACK          (NRF_ERROR_PERIPH_DRIVERS_ERR_BASE + 0x0001)
#define NRF_ERROR_DRV_TWI_ERR_DNACK          (NRF_ERROR_PERIPH_DRIVERS_ERR_BASE + 0x0002)
/** @} */


/**
 * @defgroup ble_ipsp_errors IPSP codes
 * @brief Error and status codes specific to IPSP.
 * @{
 */
#define NRF_ERROR_BLE_IPSP_RX_PKT_TRUNCATED       (NRF_ERROR_BLE_IPSP_ERR_BASE + 0x0000)
#define NRF_ERROR_BLE_IPSP_CHANNEL_ALREADY_EXISTS (NRF_ERROR_BLE_IPSP_ERR_BASE + 0x0001)
#define NRF_ERROR_BLE_IPSP_LINK_DISCONNECTED      (NRF_ERROR_BLE_IPSP_ERR_BASE + 0x0002)
#define NRF_ERROR_BLE_IPSP_PEER_REJECTED          (NRF_ERROR_BLE_IPSP_ERR_BASE + 0x0003)
/* @} */


/**
 * @brief API Result.
 *
 * @details Indicates success or failure of an API procedure. In case of failure, a comprehensive
 *          error code indicating cause or reason for failure is provided.
 *
 *          Though called an API result, it could used in Asynchronous notifications callback along
 *          with asynchronous callback as event result. This mechanism is employed when an event
 *          marks the end of procedure initiated using API. API result, in this case, will only be
 *          an indicative of whether the procedure has been requested successfully.
 */
typedef uint32_t ret_code_t;

/** @} */
/** @} */

#ifdef __cplusplus
}
#endif

#endif // SDK_ERRORS_H__
```

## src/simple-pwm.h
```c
#pragma once

#include <nrfx_pwm.h>
#include <devicetree.h>
#include <device.h>

void pwmHandler(nrfx_pwm_evt_type_t event_type, void * p_context) {
	printk("handler!\n");
}

void complexPwmExample(uint8_t pin) {
	static nrfx_pwm_t m_pwm0 = NRFX_PWM_INSTANCE(0);

	uint32_t err_code;
	nrfx_pwm_config_t const config0 = {
		.output_pins =
		{
			pin | NRFX_PWM_PIN_INVERTED,
			NRFX_PWM_PIN_NOT_USED,
			NRFX_PWM_PIN_NOT_USED,
			NRFX_PWM_PIN_NOT_USED,
		},
		.irq_priority = 7,
		.base_clock   = NRF_PWM_CLK_125kHz,
		.count_mode   = NRF_PWM_MODE_UP,
		.top_value    = 1000,
		.load_mode    = NRF_PWM_LOAD_COMMON,
		.step_mode    = NRF_PWM_STEP_AUTO
	};
	err_code = nrfx_pwm_init(&m_pwm0, &config0, pwmHandler, NULL);
	if (!err_code)
	{
		printk("NRF PWM could not be initialized: %d\n", err_code);
	}

	static nrf_pwm_values_common_t seq_values[] = {
    	0, 1000
	};

	nrf_pwm_sequence_t const seq = {
    	.values.p_common = seq_values,
    	.length          = NRF_PWM_VALUES_LENGTH(seq_values),
    	.repeats         = 0,
    	.end_delay       = 0
	};

	nrfx_pwm_simple_playback(&m_pwm0, &seq, 1, NRFX_PWM_FLAG_LOOP);
}

void simplePwmExample(uint8_t pin) {
    static nrfx_pwm_t m_pwm0 = NRFX_PWM_INSTANCE(0);

  	// see https://infocenter.nordicsemi.com/index.jsp?topic=%2Fcom.nordic.infocenter.sdk5.v15.0.0%2Fhardware_driver_pwm.html
    // low power PWM for LED blinking
	
	uint32_t err_code;
	nrfx_pwm_config_t const config0 = {
		.output_pins =
		{
			pin | NRFX_PWM_PIN_INVERTED, // channel 0
			NRFX_PWM_PIN_NOT_USED,             // channel 1
			NRFX_PWM_PIN_NOT_USED,             // channel 2
			NRFX_PWM_PIN_NOT_USED,             // channel 3
		},
		.irq_priority = 7,
		.base_clock   = NRF_PWM_CLK_125kHz,
		.count_mode   = NRF_PWM_MODE_UP,
		.top_value    = 1000,
		.load_mode    = NRF_PWM_LOAD_COMMON,
		.step_mode    = NRF_PWM_STEP_AUTO
	};
	err_code = nrfx_pwm_init(&m_pwm0, &config0, NULL, NULL);
	if (!err_code)
	{
		printk("NRF PWM could not be initialized: %d\n", err_code);
	}

	static nrf_pwm_values_common_t seq_values[] = {
    	0, 0, 0, 0, 0, 0, 0, 0, 0, 0, 1000
	};

	nrf_pwm_sequence_t const seq = {
    	.values.p_common = seq_values,
    	.length          = NRF_PWM_VALUES_LENGTH(seq_values),
    	.repeats         = 0,
    	.end_delay       = 0
	};

	while (true) {
		nrfx_pwm_simple_playback(&m_pwm0, &seq, 1, NRFX_PWM_FLAG_LOOP);
		k_msleep(10000);
		nrfx_pwm_stop(&m_pwm0, false);
		k_msleep(1000);
	}
}
```
